# DA14680 register map
Vendor: Dialog; Series: DA14680; File version: 1.2
CPU: CM0 r1p0, little endian, MPU, FPU, 3 interrupt priority bits
Registers are 16-bit, read-write, reset 0x0 unless marked. A register's access mark holds for its fields unless they carry their own. Offsets are from the block's base; [hi:lo] are bit positions.

## CACHE — CACHE registers
Base 0x400C3000
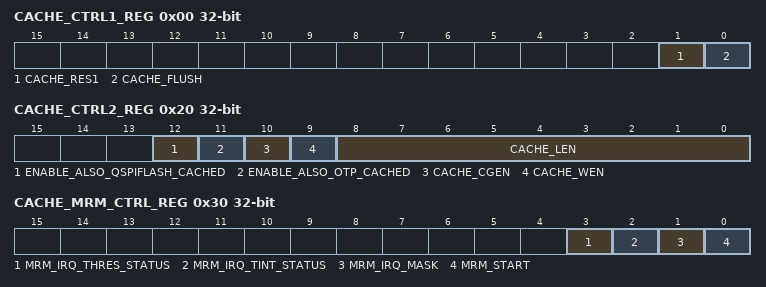
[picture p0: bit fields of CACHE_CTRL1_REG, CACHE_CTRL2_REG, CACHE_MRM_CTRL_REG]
0x00 CACHE_CTRL1_REG 32-bit — Cache control register 1
  [1] CACHE_RES1 — Reserved. Always keep 0.
  [0] CACHE_FLUSH wo — Writing a '1' into this bit, flushes the contents of the tag memories which invalidates the content of the cache memory. The read of this bit is always '0'. Note: The flushing of the cache TAG memory takes 0x100 or 0x200 HCLK cycles for a Cache Data RAM size of 8 KB resp. 16 KB.
0x04 CACHE_LNSIZECFG_REG 32-bit — Cache line size configuration register
  [1:0] CACHE_LINE — Cache line size: 0: 8 bytes, 1: 16 bytes, 2: 32 bytes, 3: reserved. Note: Flush the cache just after the dynamic (run-time) reconfiguration of the cache with an 8 bytes cache line size: write the value "01" into the cache control register CACHE_CTRL1_REG just after the write of the value "00" into the cache line size configuration register CACHE_LNSIZECFG_REG.
0x08 CACHE_ASSOCCFG_REG 32-bit reset 0x2 — Cache associativity configuration register
  [1:0] CACHE_ASSOC — Cache associativity: 0: 1-way (direct mapped) 1: 2-way 2: 4-way 3: reserved. Note: Flush the cache controller before dynamically decreasing the associativity.
0x20 CACHE_CTRL2_REG 32-bit — Cache control register 2
  [12] ENABLE_ALSO_QSPIFLASH_CACHED — Enable also the QSPI FLASH cacheability when remapped to OTP (cached). See also the notes at "CACHE_LEN".
  [11] ENABLE_ALSO_OTP_CACHED — Enable also the OTP cacheability when remapped to QSPI FLASH (cached). See also the notes at "CACHE_LEN".
  [10] CACHE_CGEN — 0: Cache controller clock gating is not enabled. 1: Cache controller clock gating is enabled (enabling power saving). Note: This bit must be set to '0' (default) when setting the CACHE_FLUSH bit while executing from other than QSPI FLASH cached or OTP cached, e.g. from Booter or SYSRAM.
  [9] CACHE_WEN — 0: Cache Data and TAG memory read only. 1: Cache Data and TAG memory read/write. The TAG and Data memory are only updated by the cache controller. There is no HW protection to prevent unauthorized access by the ARM. Note: When accessing the memory mapped Cache Data and TAG memory (for debugging purposes) only 32 bits access is allowed to the Cache Data memory and only 16 bits access is allowed to the Cache TAG memory.
  [8:0] CACHE_LEN — Length of QSPI FLASH cacheable memory. (N+1)*64kbyte. N=1 to 512 (Max of 32 Mbyte). Setting CACHE_LEN=0 disables the cache. Note 1: The OTP memory is completely cacheable (when enabled). Note 2: The max. size/length of QSPI FLASH cacheable memory is 16 Mbyte when also OTP is cached.
0x28 CACHE_MRM_HITS_REG 32-bit — Cache MRM (Miss Rate Monitor) HITS register
  [18:0] MRM_HITS — Contains the amount of cache hits.
0x2C CACHE_MRM_MISSES_REG 32-bit — Cache MRM (Miss Rate Monitor) MISSES register
  [17:0] MRM_MISSES — Contains the amount of cache misses.
0x30 CACHE_MRM_CTRL_REG 32-bit — Cache MRM (Miss Rate Monitor) CONTROL register
  [3] MRM_IRQ_THRES_STATUS — 0: No interrupt is generated. 1: Interrupt (pulse-sensitive) is generated because the number of cache misses reached the programmed threshold (threshold != 0).
  [2] MRM_IRQ_TINT_STATUS — 0: No interrupt is generated. 1: Interrupt (pulse-sensitive) is generated because the time interval counter reached the end (time interval != 0).
  [1] MRM_IRQ_MASK — 0: Disables interrupt generation. 1: Enables interrupt generation. Note: The Cache MRM generates a pulse-sensitive interrupt towards the ARM processor,
  [0] MRM_START — 0: Freeze the "misses/hits" counters and reset the time interval counter to the programmed value in CACHE_MRM_TINT_REG. 1: Enables the counters. Note: In case CACHE_MRM_CTRL_REG[MRM_START] is set to '1' and CACHE_MRM_TINT_REG (!=0) is used for the MRM interrupt generation, the time interval counter counts down (on a fixed reference clock of 16 MHz) until it's '0'. At that time CACHE_MRM_CTRL_REG[MRM_START] will be reset automatically to '0' by the MRM hardware and the MRM interrupt will be generated.
0x34 CACHE_MRM_TINT_REG 32-bit — Cache MRM (Miss Rate Monitor) TIME INTERVAL register
  [17:0] MRM_TINT — Defines the time interval for the monitoring in 16 MHz clock cycles. See also the description of CACHE_MRM_CTRL_REG[MRM_IRQ_TINT_STATUS]. Note: When MRM_TINT=0 (unrealistic value), no interrupt will be generated.
0x38 CACHE_MRM_THRES_REG 32-bit — Cache MRM (Miss Rate Monitor) THRESHOLD register
  [17:0] MRM_THRES — Defines the threshold to trigger the interrupt generation. See also the description of CACHE_MRM_CTRL_REG[MRM_IRQ_THRES_STATUS]. Note: When MRM_THRES=0 (unrealistic value), no interrupt will be generated.
0x50 SWD_RESET_REG 32-bit — SWD HW reset control register
  [0] SWD_HW_RESET_REQ wo — 0: default. 1: HW reset request without resetting the SWD and DAP controller. The register is automatically reset with a HW_RESET. This bit can only be accessed by the debugger software and not by the application.
